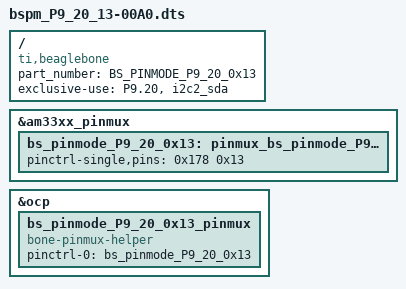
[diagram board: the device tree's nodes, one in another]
/*
 * This is a template-generated file from BoneScript
 */

/dts-v1/;
/plugin/;

/{
    compatible = "ti,beaglebone", "ti,beaglebone-black";
    part_number = "BS_PINMODE_P9_20_0x13";

    exclusive-use =
        "P9.20",
        "i2c2_sda";

    fragment@0 {
        target = <&am33xx_pinmux>;
        __overlay__ {
            bs_pinmode_P9_20_0x13: pinmux_bs_pinmode_P9_20_0x13 {
                pinctrl-single,pins = <0x178 0x13>;
            };
        };
    };

    fragment@1 {
        target = <&ocp>;
        __overlay__ {
            bs_pinmode_P9_20_0x13_pinmux {
                compatible = "bone-pinmux-helper";
                status = "okay";
                pinctrl-names = "default";
                pinctrl-0 = <&bs_pinmode_P9_20_0x13>;
            };
        };
    };
};
